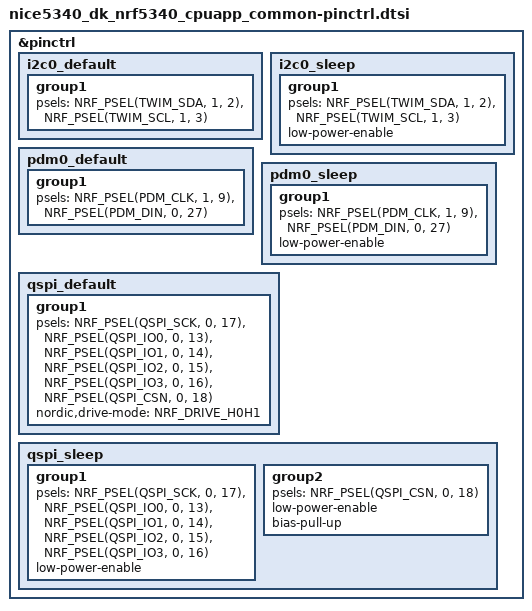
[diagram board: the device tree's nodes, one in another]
/*
 * Copyright (c) 2024 Kelly Helmut Lord
 * SPDX-License-Identifier: Apache-2.0
 */

&pinctrl {
	i2c0_default: i2c0_default {
		group1 {
			psels = <NRF_PSEL(TWIM_SDA, 1, 2)>,
				<NRF_PSEL(TWIM_SCL, 1, 3)>;
		};
	};

	i2c0_sleep: i2c0_sleep {
		group1 {
			psels = <NRF_PSEL(TWIM_SDA, 1, 2)>,
				<NRF_PSEL(TWIM_SCL, 1, 3)>;
			low-power-enable;
		};
	};

	pdm0_default: pdm0_default {
		group1 {
			psels = <NRF_PSEL(PDM_CLK, 1, 9)>,
				<NRF_PSEL(PDM_DIN, 0, 27)>;
		};
	};

	pdm0_sleep: pdm0_sleep {
		group1 {
			psels = <NRF_PSEL(PDM_CLK, 1, 9)>,
				<NRF_PSEL(PDM_DIN, 0, 27)>;
			low-power-enable;
		};
	};

	qspi_default: qspi_default {
		group1 {
			psels = <NRF_PSEL(QSPI_SCK, 0, 17)>,
				<NRF_PSEL(QSPI_IO0, 0, 13)>,
				<NRF_PSEL(QSPI_IO1, 0, 14)>,
				<NRF_PSEL(QSPI_IO2, 0, 15)>,
				<NRF_PSEL(QSPI_IO3, 0, 16)>,
				<NRF_PSEL(QSPI_CSN, 0, 18)>;
			nordic,drive-mode = <NRF_DRIVE_H0H1>;
		};
	};

	qspi_sleep: qspi_sleep {
		group1 {
			psels = <NRF_PSEL(QSPI_SCK, 0, 17)>,
				<NRF_PSEL(QSPI_IO0, 0, 13)>,
				<NRF_PSEL(QSPI_IO1, 0, 14)>,
				<NRF_PSEL(QSPI_IO2, 0, 15)>,
				<NRF_PSEL(QSPI_IO3, 0, 16)>;
			low-power-enable;
		};
		group2 {
			psels = <NRF_PSEL(QSPI_CSN, 0, 18)>;
			low-power-enable;
			bias-pull-up;
		};
	};

};
